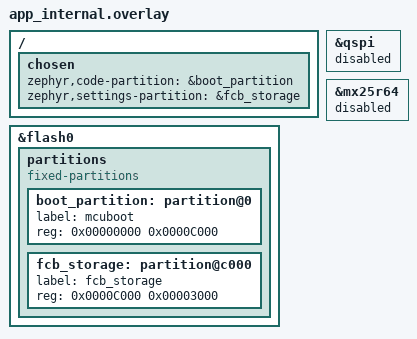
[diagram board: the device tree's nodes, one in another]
/*
 * SPDX-License-Identifier: Apache-2.0
 *
 * Devicetree overlay for Zephyr FCB / settings-on-FCB on internal nRF52840
 * NVMC flash0 (3 x 4096 B sectors at 0x0000C000..0x0000EFFF).
 */

&qspi {
    status = "disabled";
};

&mx25r64 {
    status = "disabled";
};

&flash0 {
    /delete-node/ partitions;

    partitions {
        compatible = "fixed-partitions";
        #address-cells = <1>;
        #size-cells = <1>;

        boot_partition: partition@0 {
            label = "mcuboot";
            reg = <0x00000000 0x0000C000>;
        };
        fcb_storage: partition@c000 {
            label = "fcb_storage";
            reg = <0x0000C000 0x00003000>;
        };
    };
};

/ {
    chosen {
        zephyr,code-partition = &boot_partition;
        zephyr,settings-partition = &fcb_storage;
    };
};
